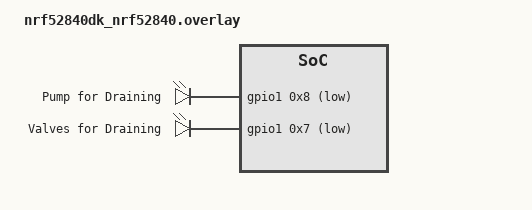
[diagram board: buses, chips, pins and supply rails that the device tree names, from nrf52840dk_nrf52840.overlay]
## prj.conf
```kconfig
#
# Copyright (c) 2019 Nordic Semiconductor ASA
#
# SPDX-License-Identifier: LicenseRef-BSD-5-Clause-Nordic
#
CONFIG_NCS_SAMPLES_DEFAULTS=y

# General configuration
CONFIG_SYSTEM_WORKQUEUE_STACK_SIZE=2048
CONFIG_FLASH=y
CONFIG_FLASH_MAP=y
CONFIG_FCB=y
CONFIG_SETTINGS=y
CONFIG_HWINFO=y
CONFIG_LOG=y
CONFIG_LOG_PRINTK=y

CONFIG_DK_LIBRARY=y
CONFIG_BT_MESH_DK_PROV=y

# Bluetooth configuration
CONFIG_BT=y
CONFIG_BT_COMPANY_ID=0x0059
CONFIG_BT_DEVICE_NAME="Drainage System"
CONFIG_BT_L2CAP_TX_MTU=69
CONFIG_BT_L2CAP_TX_BUF_COUNT=8
CONFIG_BT_LL_SW_SPLIT=y
CONFIG_BT_OBSERVER=y
CONFIG_BT_PERIPHERAL=y
CONFIG_BT_SETTINGS=y
CONFIG_BT_MAX_CONN=3

# Disable unused Bluetooth features
CONFIG_BT_CTLR_DUP_FILTER_LEN=0
CONFIG_BT_CTLR_LE_ENC=n
CONFIG_BT_DATA_LEN_UPDATE=n
CONFIG_BT_PHY_UPDATE=n
CONFIG_BT_CTLR_CHAN_SEL_2=n
CONFIG_BT_CTLR_MIN_USED_CHAN=n
CONFIG_BT_CTLR_PRIVACY=n

# Bluetooth Mesh configuration
CONFIG_BT_MESH=y
CONFIG_BT_MESH_RELAY=y
CONFIG_BT_MESH_FRIEND=y
CONFIG_BT_MESH_ADV_BUF_COUNT=13
CONFIG_BT_MESH_TX_SEG_MAX=10
CONFIG_BT_MESH_PB_GATT=y
CONFIG_BT_MESH_GATT_PROXY=y

# Bluetooth Mesh models
CONFIG_BT_MESH_ONOFF_SRV=y
CONFIG_BT_MESH_ONOFF_CLI=y
CONFIG_BT_MESH_LVL_SRV=y

#For Reset
CONFIG_REBOOT=y

#For nRF52 Dongle (enable if flashed over USB / Disable if FLashed over SWD)
CONFIG_BOARD_HAS_NRF5_BOOTLOADER=y
```

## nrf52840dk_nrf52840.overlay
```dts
/ {
    leds {
		compatible = "gpio-leds";
		pumpdrain: pump_drain {
			gpios = < &gpio1 0x8 0x11 >;
			label = "Pump for Draining";
		};
		valvesdrain: valves_drain {
			gpios = < &gpio1 0x7 0x11 >;
			label = "Valves for Draining";
		};
    };
	aliases {
		pumpdrain = &pumpdrain;
		valvesdrain = &valvesdrain;
	};
};
```

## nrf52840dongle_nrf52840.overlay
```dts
/ {
    leds {
		compatible = "gpio-leds";
		pumpdrain: pump_drain {
			gpios = < &gpio1 0xd 0x11 >;
			label = "Pump for Draining";
		};
		valvesdrain: valves_drain {
			gpios = < &gpio1 0xa 0x11 >;
			label = "Valves for Draining";
		};
    };
	aliases {
		pumpdrain = &pumpdrain;
		valvesdrain = &valvesdrain;
	};
};
```

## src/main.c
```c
#include "bm_blemesh.h"
#include "bm_simple_buttons_and_leds.h"
#include <zephyr.h>
#include <sys/reboot.h>
#include <bm_draniage_system.h>

/**@brief For Reseting the System
 */
void reset(){
  printk("Reboot now!\n");
  sys_reboot(SYS_REBOOT_COLD);
}

/**@brief Function for application main entry.
 */
void main(void) {
  // Start Application
  printk("Starting Application...\n");
  // Init MAC Address
  uint32_t LSB_MAC_Address = NRF_FICR->DEVICEADDR[0];
  printk("Preprogrammed Randomly Static MAC-Address (LSB): 0x%x, %u \n", LSB_MAC_Address, LSB_MAC_Address);
  // Init Leds
  bm_init_leds();
  //Init Reset Buttons
  bm_init_buttons(reset);
  // Start Mesh Operation
  bm_blemesh_enable(); // Will return faster than the Stack is realy ready... keep on waiting in the transition.

  while(true){
    bm_drainage_stateMachine();
    k_sleep(K_MSEC(1000));
  }

}
```

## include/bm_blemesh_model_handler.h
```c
/*
This file is part of Bluetooth-Benchamrk.

Bluetooth-Benchamrk is free software: you can redistribute it and/or modify
it under the terms of the GNU General Public License as published by
the Free Software Foundation, either version 3 of the License, or
(at your option) any later version.

Bluetooth-Benchamrk is distributed in the hope that it will be useful,
but WITHOUT ANY WARRANTY; without even the implied warranty of
MERCHANTABILITY or FITNESS FOR A PARTICULAR PURPOSE.  See the
GNU General Public License for more details.

You should have received a copy of the GNU General Public License
along with Bluetooth-Benchamrk.  If not, see <http://www.gnu.org/licenses/>.
*/

/* AUTHOR 	 :    Raffael Anklin       */

#ifndef MODEL_HANDLER_H__
#define MODEL_HANDLER_H__

#include <bm_draniage_system.h>
#include <bluetooth/mesh/models.h>


#ifdef __cplusplus
extern "C" {
#endif

extern struct bt_mesh_onoff_cli valve_drain_on_off_cli[NUMBER_OF_VALVES];

const struct bt_mesh_comp *bm_blemesh_model_handler_init(void);


#ifdef __cplusplus
}
#endif

#endif /* MODEL_HANDLER_H__ */
```

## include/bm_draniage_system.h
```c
#ifndef BM_DRAINAGE_H
#define BM_DRAINAGE_H

#define NUMBER_OF_VALVES 8

extern int16_t drain_intervall_h;
extern int16_t valve_drain_time_s[NUMBER_OF_VALVES];

void bm_drainage_stateMachine();



#endif
```

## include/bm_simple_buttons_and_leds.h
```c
/*
This file is part of Benchamrk-Shared-Library.

Benchamrk-Shared-Library is free software: you can redistribute it and/or modify
it under the terms of the GNU General Public License as published by
the Free Software Foundation, either version 3 of the License, or
(at your option) any later version.

Benchamrk-Shared-Library is distributed in the hope that it will be useful,
but WITHOUT ANY WARRANTY; without even the implied warranty of
MERCHANTABILITY or FITNESS FOR A PARTICULAR PURPOSE.  See the
GNU General Public License for more details.

You should have received a copy of the GNU General Public License
along with Benchamrk-Shared-Library.  If not, see <http://www.gnu.org/licenses/>.
*/

/* AUTHOR ZEPHYR_BLE_MESH  :   Raffael Anklin        */
/* AUTHOR NRF_SDK_ZIGBEE   :   Cyrill Horath        */


#ifdef __cplusplus
extern "C" {
#endif

#ifndef SIMPLE_BUTTONS_AND_LEDS_H
#define SIMPLE_BUTTONS_AND_LEDS_H


#include <zephyr.h>
#include <device.h>
#include <devicetree.h>
#include <devicetree_unfixed.h>
#include <drivers/gpio.h>
#include <sys/util.h>
#include <sys/slist.h>

/*
 * Devicetree helper macro which gets the 'flags' cell from a 'gpios'
 * property, or returns 0 if the property has no 'flags' cell.
 */

#define FLAGS_OR_ZERO(node)						\
	COND_CODE_1(DT_PHA_HAS_CELL(node, gpios, flags),		\
		    (DT_GPIO_FLAGS(node, gpios)),			\
		    (0))



/* The devicetree node identifier for the "led0" alias. */
#define LED0_NODE DT_ALIAS(led0)

#if DT_NODE_HAS_STATUS(LED0_NODE, okay)
#define LED0	DT_GPIO_LABEL(LED0_NODE, gpios)
#define PIN_LED0	DT_GPIO_PIN(LED0_NODE, gpios)
#if DT_PHA_HAS_CELL(LED0_NODE, gpios, flags)
#define FLAGS_LED0	DT_GPIO_FLAGS(LED0_NODE, gpios)
#endif
#else
/* A build error here means your board isn't set up to blink an LED. */
#error "Unsupported board: led0 devicetree alias is not defined"
#define LED0	""
#define PIN_LED0	0
#endif

#ifndef FLAGS_LED0
#define FLAGS_LED0	0
#endif

/* The devicetree node identifier for the "led1" alias. Is the RED LED on THe nRF52 Donlge*/
#define LED1_NODE DT_ALIAS(led1)

#if DT_NODE_HAS_STATUS(LED1_NODE, okay)
#define LED1	DT_GPIO_LABEL(LED1_NODE, gpios)
#define PIN_LED1	DT_GPIO_PIN(LED1_NODE, gpios)
#if DT_PHA_HAS_CELL(LED1_NODE, gpios, flags)
#define FLAGS_LED1	DT_GPIO_FLAGS(LED1_NODE, gpios)
#endif
#else
/* A build error here means your board isn't set up to blink an LED. */
#error "Unsupported board: led1 devicetree alias is not defined"
#define LED1	""
#define PIN_LED1	0
#endif

#ifndef FLAGS_LED1
#define FLAGS_LED1	0
#endif


/* The devicetree node identifier for the "led2" alias. Is the GREEN LED on THe nRF52 Donlge*/
#define LED2_NODE DT_ALIAS(led2)

#if DT_NODE_HAS_STATUS(LED2_NODE, okay)
#define LED2	DT_GPIO_LABEL(LED2_NODE, gpios)
#define PIN_LED2	DT_GPIO_PIN(LED2_NODE, gpios)
#if DT_PHA_HAS_CELL(LED2_NODE, gpios, flags)
#define FLAGS_LED2	DT_GPIO_FLAGS(LED2_NODE, gpios)
#endif
#else
/* A build error here means your board isn't set up to blink an LED. */
#error "Unsupported board: led2 devicetree alias is not defined"
#define LED2	""
#define PIN_LED2	0
#endif

#ifndef FLAGS_LED2
#define FLAGS_LED1	0
#endif

/* The devicetree node identifier for the "led3" alias. Is the BLUE LED on THe nRF52 Donlge*/
#define LED3_NODE DT_ALIAS(led3)

#if DT_NODE_HAS_STATUS(LED3_NODE, okay)
#define LED3	DT_GPIO_LABEL(LED3_NODE, gpios)
#define PIN_LED3	DT_GPIO_PIN(LED3_NODE, gpios)
#if DT_PHA_HAS_CELL(LED3_NODE, gpios, flags)
#define FLAGS_LED3	DT_GPIO_FLAGS(LED3_NODE, gpios)
#endif
#else
/* A build error here means your board isn't set up to blink an LED. */
#error "Unsupported board: led3 devicetree alias is not defined"
#define LED3	""
#define PIN_LED3	0
#endif

#ifndef FLAGS_LED3
#define FLAGS_LED3	0
#endif

/* The devicetree node identifier for the "pumpdrain" alias.*/
#define PUMPDRAIN_NODE DT_ALIAS(pumpdrain)

#if DT_NODE_HAS_STATUS(PUMPDRAIN_NODE, okay)
#define PUMPDRAIN	DT_GPIO_LABEL(PUMPDRAIN_NODE, gpios)
#define PIN_PUMPDRAIN	DT_GPIO_PIN(PUMPDRAIN_NODE, gpios)
#if DT_PHA_HAS_CELL(PUMPDRAIN_NODE, gpios, flags)
#define FLAGS_PUMPDRAIN	DT_GPIO_FLAGS(PUMPDRAIN_NODE, gpios)
#endif
#else
/* A build error here means your board isn't set up to blink an LED. */
#error "Unsupported board: pumpdrain devicetree alias is not defined"
#define PUMPDRAIN	""
#define PIN_PUMPDRAIN	0
#endif

#ifndef FLAGS_PUMPDRAIN
#define FLAGS_PUMPDRAIN	0
#endif

/* The devicetree node identifier for the "valvesdrain" alias.*/
#define VALVESDRAIN_NODE DT_ALIAS(valvesdrain)

#if DT_NODE_HAS_STATUS(VALVESDRAIN_NODE, okay)
#define VALVESDRAIN	DT_GPIO_LABEL(VALVESDRAIN_NODE, gpios)
#define PIN_VALVESDRAIN	DT_GPIO_PIN(VALVESDRAIN_NODE, gpios)
#if DT_PHA_HAS_CELL(VALVESDRAIN_NODE, gpios, flags)
#define FLAGS_VALVESDRAIN	DT_GPIO_FLAGS(VALVESDRAIN_NODE, gpios)
#endif
#else
/* A build error here means your board isn't set up to blink an LED. */
#error "Unsupported board: valvesdrain devicetree alias is not defined"
#define VALVESDRAIN	""
#define PIN_VALVESDRAIN	0
#endif

#ifndef FLAGS_VALVESDRAIN
#define FLAGS_VALVESDRAIN	0
#endif


/*
 * Get button configuration from the devicetree sw0 alias.
 *
 * At least a GPIO device and pin number must be provided. The 'flags'
 * cell is optional.
 */

#define SW0_NODE	DT_ALIAS(sw0)

#if DT_NODE_HAS_STATUS(SW0_NODE, okay)
#define SW0_GPIO_LABEL	DT_GPIO_LABEL(SW0_NODE, gpios)
#define SW0_GPIO_PIN	DT_GPIO_PIN(SW0_NODE, gpios)
#define SW0_GPIO_FLAGS	(GPIO_INPUT | FLAGS_OR_ZERO(SW0_NODE) | GPIO_INT_DEBOUNCE)
#else
#error "Unsupported board: sw0 devicetree alias is not defined"
#define SW0_GPIO_LABEL	""
#define SW0_GPIO_PIN	0
#define SW0_GPIO_FLAGS	0
#endif




/**
* Init the Buttons
*
*/
void bm_init_buttons(void (*button0_cb)());

/**
* Get the BUTTON0 Pressed State
*
* @return State of the BUTTON0 Pressed (0/1)
*/
bool bm_button0_pressed_state_get();
/**
* Get the BUTTON0 Toggled State
*
* @return State of the BUTTON0 Toggled State (0/1)
*/
bool bm_button0_toggle_state_get();

/**
* Set the BUTTON0 Toggled State
*
* @param State of the BUTTON0 Toggled State (0/1)
*/
void bm_button0_toggle_state_set(bool newstate);



/**
* Init the Leds
*
*/
void bm_init_leds();

/**
* Set the LED0 State
*
* @param State to set the LED0 to (0/1) (GREEN no RGB on nRF52 Dongle / LED1 on nRF52 DK)
*/
void bm_led0_set(bool state);

/**
* Get the LED0 State
*
* @return State of the LED0 (0/1) (GREEN no RGB on nRF52 Dongle / LED1 on nRF52 DK)
*/
bool bm_led0_get();


/**
* Set the LED1 State
*
* @param State to set the LED1 to (0/1) (RED on nRF52 Dongle / LED2 on nRF52 DK)
*/
void bm_led1_set(bool state);

/**
* Get the LED1 State
*
* @return State of the LED1 (0/1) (RED on nRF52 Dongle / LED2 on nRF52 DK)
*/
bool bm_led1_get();

/**
* Set the LED2 State
*
* @param State to set the LED2 to (0/1) (GREEN on nRF52 Dongle / LED3 on nRF52 DK)
*/
void bm_led2_set(bool state);

/**
* Get the LED2 State
*
* @return State of the LED2 (0/1) (GREEN on nRF52 Dongle / LED3 on nRF52 DK)
*/
bool bm_led2_get();

/**
* Set the LED3 State
*
* @param State to set the LED3 to (0/1) (BLUE on nRF52 Dongle / LED4 on nRF52 DK)
*/
void bm_led3_set(bool state);

/**
* Get the LED3 State
*
* @return State of the LED3 (0/1) (BLUE on nRF52 Dongle / LED4 on nRF52 DK)
*/
bool bm_led3_get();


/**
* Set the PUMPDRAIN State
*
* @param State to set the PUMPDRAIN to (0/1)
*/
void bm_pumpdrain_set(bool state);

/**
* Get the PUMPDRAIN State
*
* @return State of the PUMPDRAIN (0/1)
*/
bool bm_pumpdrain_get();

/**
* Set the VALVESDRAIN State
*
* @param State to set the VALVESDRAIN to (0/1)
*/
void bm_valvesdrain_set(bool state);

/**
* Get the VALVESDRAIN State
*
* @return State of the VALVESDRAIN (0/1)
*/
bool bm_valvesdrain_get();


#endif

#ifdef __cplusplus
}
#endif
```

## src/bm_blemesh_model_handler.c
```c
/*
This file is part of Bluetooth-Benchamrk.

Bluetooth-Benchamrk is free software: you can redistribute it and/or modify
it under the terms of the GNU General Public License as published by
the Free Software Foundation, either version 3 of the License, or
(at your option) any later version.

Bluetooth-Benchamrk is distributed in the hope that it will be useful,
but WITHOUT ANY WARRANTY; without even the implied warranty of
MERCHANTABILITY or FITNESS FOR A PARTICULAR PURPOSE.  See the
GNU General Public License for more details.

You should have received a copy of the GNU General Public License
along with Bluetooth-Benchamrk.  If not, see <http://www.gnu.org/licenses/>.
*/

/* AUTHOR 	 :    Raffael Anklin       */


#include "bm_simple_buttons_and_leds.h"
#include "bm_blemesh.h"
#include "bm_blemesh_model_handler.h"

#include <bluetooth/bluetooth.h>
#include <bluetooth/mesh/models.h>
#include <bluetooth/mesh/model_types.h>

#include <bm_draniage_system.h>


/* ============================================== Element 1 ============================== */

/** ON/OFF Server definition */
static void pump_set(struct bt_mesh_onoff_srv *srv, struct bt_mesh_msg_ctx *ctx,
					const struct bt_mesh_onoff_set *set,
					struct bt_mesh_onoff_status *rsp)
{
	// Set DK LED index
	bm_pumpdrain_set(set->on_off);
}

static void pump_get(struct bt_mesh_onoff_srv *srv, struct bt_mesh_msg_ctx *ctx,
					struct bt_mesh_onoff_status *rsp)
{
	rsp->present_on_off = bm_pumpdrain_get();
}

static const struct bt_mesh_onoff_srv_handlers pump_onoff_handlers = {
	.set = pump_set,
	.get = pump_get,
};

static struct bt_mesh_onoff_srv pump_on_off_srv = BT_MESH_ONOFF_SRV_INIT(&pump_onoff_handlers);

/** Convert level to percent */
static int16_t level_to_percent(int16_t level){
	return (double)((double)level+BT_MESH_LVL_MAX)*100/(BT_MESH_LVL_MAX*2);
}

/** Convert percent to level */
static int16_t percent_to_level(int16_t percent){
	return ((percent*2*BT_MESH_LVL_MAX)/100)-BT_MESH_LVL_MAX;
}

/** Time Drainage Intervall LEVEL Server definition */
static void drain_intervall_h_get(struct bt_mesh_lvl_srv *srv, struct bt_mesh_msg_ctx *ctx,
					struct bt_mesh_lvl_status *rsp)
{
	printk("Waittime get is %u hours\n",drain_intervall_h);
	rsp->current = percent_to_level(drain_intervall_h);
}
static void drain_intervall_h_set(struct bt_mesh_lvl_srv *srv, struct bt_mesh_msg_ctx *ctx,
					const struct bt_mesh_lvl_set *set,
					struct bt_mesh_lvl_status *rsp)
{
	drain_intervall_h = level_to_percent(set->lvl);
	printk("Waittime set is %u hours\n",drain_intervall_h);
}
static void dummy_delta_set(struct bt_mesh_lvl_srv *srv,
				struct bt_mesh_msg_ctx *ctx,
				const struct bt_mesh_lvl_delta_set *delta_set,
				struct bt_mesh_lvl_status *rsp)
{ 
	printk("Not Supported\n");
}
static void dummy_h_move_set(struct bt_mesh_lvl_srv *srv,
			       struct bt_mesh_msg_ctx *ctx,
			       const struct bt_mesh_lvl_move_set *move_set,
			       struct bt_mesh_lvl_status *rsp)
{
	printk("Not Supported\n");
}
static const struct bt_mesh_lvl_srv_handlers drain_intervall_h_lvl_handlers = {
	.set = drain_intervall_h_set,
	.get = drain_intervall_h_get,
	.delta_set = dummy_delta_set,
	.move_set = dummy_h_move_set
};
static struct bt_mesh_lvl_srv drain_intervall_h_lvl_srv = BT_MESH_LVL_SRV_INIT(&drain_intervall_h_lvl_handlers);

/** Health Server definition */
static void attention_on(struct bt_mesh_model *model)
{
	printk("attention_on()\n");
}

static void attention_off(struct bt_mesh_model *model)
{
	printk("attention_off()\n");
}
static const struct bt_mesh_health_srv_cb health_srv_cb = {
	.attn_on = attention_on,
	.attn_off = attention_off,
};

static struct bt_mesh_health_srv health_srv = {
	.cb = &health_srv_cb,
};

BT_MESH_HEALTH_PUB_DEFINE(health_pub, 0);


/* ============================================== Valve Elements ============================== */

/** ON/OFF Client definition */
struct bt_mesh_onoff_cli valve_drain_on_off_cli[NUMBER_OF_VALVES] = {
	[0 ... NUMBER_OF_VALVES -1] =  BT_MESH_ONOFF_CLI_INIT(NULL) ,
};

/** Drain Valves Open Time Seconds LEVEL Server definition */
static void valve_drain_time_s_get(struct bt_mesh_lvl_srv *srv, struct bt_mesh_msg_ctx *ctx,
					struct bt_mesh_lvl_status *rsp)
{
	rsp->current = percent_to_level(valve_drain_time_s[srv->model->elem_idx - 1]);
}
static void valve_drain_time_s_set(struct bt_mesh_lvl_srv *srv, struct bt_mesh_msg_ctx *ctx,
					const struct bt_mesh_lvl_set *set,
					struct bt_mesh_lvl_status *rsp)
{
	valve_drain_time_s[srv->model->elem_idx - 1] = level_to_percent(set->lvl);
}
static const struct bt_mesh_lvl_srv_handlers valve_drain_time_s_lvl_handlers = {
	.set = valve_drain_time_s_set,
	.get = valve_drain_time_s_get,
	.delta_set = dummy_delta_set,
	.move_set = dummy_h_move_set
};
static struct bt_mesh_lvl_srv valve_drain_time_s_lvl_srv[NUMBER_OF_VALVES] = {
	[0 ... NUMBER_OF_VALVES -1] =  BT_MESH_LVL_SRV_INIT(&valve_drain_time_s_lvl_handlers) ,
};




/* Define all Elements */
static struct bt_mesh_elem elements[1+ NUMBER_OF_VALVES] = {
	BT_MESH_ELEM(
		1, BT_MESH_MODEL_LIST(BT_MESH_MODEL_CFG_SRV, BT_MESH_MODEL_HEALTH_SRV(&health_srv, &health_pub), BT_MESH_MODEL_ONOFF_SRV(&pump_on_off_srv), BT_MESH_MODEL_LVL_SRV(&drain_intervall_h_lvl_srv)),
		BT_MESH_MODEL_NONE),
	BT_MESH_ELEM(
		2, BT_MESH_MODEL_LIST(BT_MESH_MODEL_ONOFF_CLI(&valve_drain_on_off_cli[0]), BT_MESH_MODEL_LVL_SRV(&valve_drain_time_s_lvl_srv[0])),
		BT_MESH_MODEL_NONE),
	BT_MESH_ELEM(
		3, BT_MESH_MODEL_LIST(BT_MESH_MODEL_ONOFF_CLI(&valve_drain_on_off_cli[1]), BT_MESH_MODEL_LVL_SRV(&valve_drain_time_s_lvl_srv[1])),
		BT_MESH_MODEL_NONE),
		BT_MESH_ELEM(
		4, BT_MESH_MODEL_LIST(BT_MESH_MODEL_ONOFF_CLI(&valve_drain_on_off_cli[2]), BT_MESH_MODEL_LVL_SRV(&valve_drain_time_s_lvl_srv[2])),
		BT_MESH_MODEL_NONE),
		BT_MESH_ELEM(
		5, BT_MESH_MODEL_LIST(BT_MESH_MODEL_ONOFF_CLI(&valve_drain_on_off_cli[3]), BT_MESH_MODEL_LVL_SRV(&valve_drain_time_s_lvl_srv[3])),
		BT_MESH_MODEL_NONE),
		BT_MESH_ELEM(
		6, BT_MESH_MODEL_LIST(BT_MESH_MODEL_ONOFF_CLI(&valve_drain_on_off_cli[4]), BT_MESH_MODEL_LVL_SRV(&valve_drain_time_s_lvl_srv[4])),
		BT_MESH_MODEL_NONE),
		BT_MESH_ELEM(
		7, BT_MESH_MODEL_LIST(BT_MESH_MODEL_ONOFF_CLI(&valve_drain_on_off_cli[5]), BT_MESH_MODEL_LVL_SRV(&valve_drain_time_s_lvl_srv[5])),
		BT_MESH_MODEL_NONE),
		BT_MESH_ELEM(
		8, BT_MESH_MODEL_LIST(BT_MESH_MODEL_ONOFF_CLI(&valve_drain_on_off_cli[6]), BT_MESH_MODEL_LVL_SRV(&valve_drain_time_s_lvl_srv[6])),
		BT_MESH_MODEL_NONE),
		BT_MESH_ELEM(
		9, BT_MESH_MODEL_LIST(BT_MESH_MODEL_ONOFF_CLI(&valve_drain_on_off_cli[7]), BT_MESH_MODEL_LVL_SRV(&valve_drain_time_s_lvl_srv[7])),
		BT_MESH_MODEL_NONE)
				};



/* Create Composition */
const struct bt_mesh_comp comp = {
	.cid = CONFIG_BT_COMPANY_ID,
	.elem = elements,
	.elem_count = ARRAY_SIZE(elements),
};

const struct bt_mesh_comp *bm_blemesh_model_handler_init(void)
{
	return &comp;
}
```

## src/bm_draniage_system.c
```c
/*
 * Copyright (c) 2016 Intel Corporation
 * Copyright (c) 2020 Nordic Semiconductor ASA
 *
 * SPDX-License-Identifier: Apache-2.0
 */

/**
 * @file Drainage System with Flowchart
 */

#include <zephyr.h>
#include <sys/printk.h>
#include <device.h>
#include <bm_draniage_system.h>
#include <bm_blemesh_model_handler.h>
#include <bluetooth/mesh/models.h>
#include <bm_simple_buttons_and_leds.h>

typedef enum {INIT,
				WAIT,
				CLOSE_ALL,
				DRAIN_VALVES,
				OPEN_ALL}  state_t;
 
state_t state = INIT;

int16_t drain_intervall_h = 12;
int16_t valve_drain_time_s[NUMBER_OF_VALVES] = {
	[0 ... NUMBER_OF_VALVES -1] = 10,
};

static int ret;
static struct bt_mesh_onoff_set set = {.on_off = false,};

void bm_drainage_stateMachine()
{
switch( state ) {
	case INIT:
		printk("State: INIT\n");
		bm_pumpdrain_set(false);
		bm_valvesdrain_set(false);
		k_sleep(K_MSEC(500));
      	state = CLOSE_ALL;
      	break;

    case CLOSE_ALL:
		printk("State: CLOSE_ALL\n");
		bm_valvesdrain_set(true);
		k_sleep(K_MSEC(2000));
	  	for (size_t i = 0; i < NUMBER_OF_VALVES; i++)
	  	{
			set.on_off = false;
			ret = bt_mesh_onoff_cli_set_unack(&valve_drain_on_off_cli[i],NULL,&set);
			k_sleep(K_MSEC(100));
	  	}	  
      	state = DRAIN_VALVES;
      	break;    
	
	case DRAIN_VALVES:
		printk("State: DRAIN_VALVES\n");
		bm_pumpdrain_set(true);
	  	for (size_t i = 0; i < NUMBER_OF_VALVES; i++)
	  	{
			set.on_off = true;
			ret = bt_mesh_onoff_cli_set_unack(&valve_drain_on_off_cli[i],NULL,&set);
			k_sleep(K_MSEC(valve_drain_time_s[i]*1000));
			set.on_off = false;
			ret = bt_mesh_onoff_cli_set_unack(&valve_drain_on_off_cli[i],NULL,&set);
			k_sleep(K_MSEC(500));
	  	}	  
      	state = OPEN_ALL;
      	break; 
	
	case OPEN_ALL:
		printk("State: OPEN_ALL\n");
	  	for (size_t i = 0; i < NUMBER_OF_VALVES; i++)
	  	{
			set.on_off = true;
			ret = bt_mesh_onoff_cli_set_unack(&valve_drain_on_off_cli[i],NULL,&set);
			k_sleep(K_MSEC(100));
	  	}	  
      	state = WAIT;
      	break; 
	
	case WAIT:
		printk("State: WAIT\n");
		bm_valvesdrain_set(false);
		bm_pumpdrain_set(false);
		printk("Wait for %u hours\n",drain_intervall_h);
      	k_sleep(K_HOURS(drain_intervall_h));
      	state = CLOSE_ALL;
      	break;
  }
}
```

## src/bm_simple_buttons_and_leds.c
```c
/*
This file is part of Benchmark-Shared-Library.

Benchmark-Shared-Library is free software: you can redistribute it and/or modify
it under the terms of the GNU General Public License as published by
the Free Software Foundation, either version 3 of the License, or
(at your option) any later version.

Benchmark-Shared-Library is distributed in the hope that it will be useful,
but WITHOUT ANY WARRANTY; without even the implied warranty of
MERCHANTABILITY or FITNESS FOR A PARTICULAR PURPOSE.  See the
GNU General Public License for more details.

You should have received a copy of the GNU General Public License
along with Benchmark-Shared-Library.  If not, see <http://www.gnu.org/licenses/>.
*/

/* AUTHOR ZEPHYR_BLE_MESH  :   Raffael Anklin        */
/* AUTHOR NRF_SDK_ZIGBEE   :   Cyrill Horath        */

#include "bm_simple_buttons_and_leds.h"


const struct device *dev_led0, *dev_led1, *dev_led2, *dev_led3, *dev_pumpdrain, *dev_valvesdrain, *dev_button0;
bool led0_is_on, led1_is_on, led2_is_on, led3_is_on, pumpdrain_is_on, valvesdrain_is_on = true;
bool button0_toggel_state = true;
int ret;

static struct gpio_callback button_cb_data;

static struct k_work_delayable buttons_debounce;

static void (*button0_callback)();

static void buttons_debounce_fn(struct k_work *work) {
  if(gpio_pin_get(dev_button0,SW0_GPIO_PIN)==true){
      button0_toggel_state = !button0_toggel_state;
      button0_callback();
  }
}


void button_pressed(const struct device *port,
					struct gpio_callback *cb,
					gpio_port_pins_t pins) {
  if (port == dev_button0) {
    k_work_reschedule(&buttons_debounce, K_MSEC(5*1000)); // Debounce the Button
                                                           //button0_callback();
  }
}

gpio_callback_handler_t button_pressed_handler = &button_pressed;


/* Init the Buttons */
void bm_init_buttons(void (*button0_cb)()) {
  dev_button0 = device_get_binding(SW0_GPIO_LABEL);
  if (dev_button0 == NULL) {
    printk("Error: didn't find %s device\n", SW0_GPIO_LABEL);
    return;
  }
  ret = gpio_pin_configure(dev_button0, SW0_GPIO_PIN, SW0_GPIO_FLAGS);
  if (ret != 0) {
    printk("Error %d: failed to configure %s pin %d\n",
        ret, SW0_GPIO_LABEL, SW0_GPIO_PIN);
    return;
  }
  ret = gpio_pin_interrupt_configure(dev_button0,
      SW0_GPIO_PIN,
      GPIO_INT_EDGE_TO_ACTIVE);
  if (ret != 0) {
    printk("Error %d: failed to configure interrupt on %s pin %d\n",
        ret, SW0_GPIO_LABEL, SW0_GPIO_PIN);
    return;
  }

  gpio_init_callback(&button_cb_data, button_pressed_handler, BIT(SW0_GPIO_PIN));
  gpio_add_callback(dev_button0, &button_cb_data);
  printk("Set up button at %s pin %d\n", SW0_GPIO_LABEL, SW0_GPIO_PIN);
  button0_callback = button0_cb;

  k_work_init_delayable(&buttons_debounce, buttons_debounce_fn);
}



/* Init the Leds */
void bm_init_leds() {
  dev_led0 = device_get_binding(LED0);
  if (dev_led0 == NULL) {
    printk("Error no LED0 found");
    return;
  }
  ret = gpio_pin_configure(dev_led0, PIN_LED0, GPIO_OUTPUT_INACTIVE | FLAGS_LED0);
  if (ret < 0) {
    printk("Error in configuration of led0 pin (err %d)", ret);
    return;
  }
  dev_led1 = device_get_binding(LED1);
  if (dev_led1 == NULL) {
    printk("Error no LED1 found");
    return;
  }
  ret = gpio_pin_configure(dev_led1, PIN_LED1, GPIO_OUTPUT_INACTIVE | FLAGS_LED1);
  if (ret < 0) {
    printk("Error in configuration of led1 pin (err %d)", ret);
    return;
  }
  dev_led2 = device_get_binding(LED2);
  if (dev_led2 == NULL) {
    printk("Error no LED2 found");
    return;
  }
  ret = gpio_pin_configure(dev_led2, PIN_LED2, GPIO_OUTPUT_INACTIVE | FLAGS_LED2);
  if (ret < 0) {
    printk("Error in configuration of led2 pin (err %d)", ret);
    return;
  }
  dev_led3 = device_get_binding(LED3);
  if (dev_led3 == NULL) {
    printk("Error no LED3 found");
    return;
  }
  ret = gpio_pin_configure(dev_led3, PIN_LED3, GPIO_OUTPUT_INACTIVE | FLAGS_LED3);
  if (ret < 0) {
    printk("Error in configuration of led3 pin (err %d)", ret);
    return;
  }

  dev_pumpdrain = device_get_binding(PUMPDRAIN);
  if (dev_pumpdrain == NULL) {
    printk("Error no PUMPDRAIN found");
    return;
  }
  ret = gpio_pin_configure(dev_pumpdrain, PIN_PUMPDRAIN, GPIO_OUTPUT_ACTIVE | FLAGS_PUMPDRAIN);
  if (ret < 0) {
    printk("Error in configuration of pumpdrain pin (err %d)", ret);
    return;
  }

  dev_valvesdrain = device_get_binding(VALVESDRAIN);
  if (dev_valvesdrain == NULL) {
    printk("Error no VALVESDRAIN found");
    return;
  }
  ret = gpio_pin_configure(dev_valvesdrain, PIN_VALVESDRAIN, GPIO_OUTPUT_ACTIVE | FLAGS_VALVESDRAIN);
  if (ret < 0) {
    printk("Error in configuration of valvesdrain pin (err %d)", ret);
    return;
  }


}


/* Set LED0. pca10059 -> Green LED */
void bm_led0_set(bool state) {
  gpio_pin_set(dev_led0, PIN_LED0, (int)state);
  led0_is_on = state;
}

/* Get LED0 */
bool bm_led0_get() {
  return led0_is_on;
}

/* Set LED1. pca10059 -> Red LED (RGB) */
void bm_led1_set(bool state) {
  gpio_pin_set(dev_led1, PIN_LED1, (int)state);
  led1_is_on = state;
}

/* Get LED1 */
bool bm_led1_get() {
  return led1_is_on;
}

/* Set LED2. pca10059 -> Green LED (RGB) */
void bm_led2_set(bool state) {
  gpio_pin_set(dev_led2, PIN_LED2, (int)state);
  led2_is_on = state;
}

/* Get LED2 */
bool bm_led2_get() {
  return led2_is_on;
}

/* Set LED3. pca10059 -> Blue LED (RGB)  */
void bm_led3_set(bool state) {
  gpio_pin_set(dev_led3, PIN_LED3, (int)state);
  led3_is_on = state;
}

/* Get LED3 */
bool bm_led3_get() {
  return led3_is_on;
}


/* Set PUMPDRAIN  */
void bm_pumpdrain_set(bool state) {
  gpio_pin_set(dev_pumpdrain, PIN_PUMPDRAIN, (int)state);
  pumpdrain_is_on = !state;
}

/* Get PUMPDRAIN */
bool bm_pumpdrain_get() {
  return pumpdrain_is_on;
}

/* Set VALVESDRAIN  */
void bm_valvesdrain_set(bool state) {
  gpio_pin_set(dev_valvesdrain, PIN_VALVESDRAIN, (int)state);
  valvesdrain_is_on = !state;
}

/* Get PUMPDRAIN */
bool bm_valvesdrain_get() {
  return valvesdrain_is_on;
}


/* Get BUTTON0 Pressed State*/
bool bm_button0_pressed_state_get() {
   return (bool) gpio_pin_get(dev_button0, SW0_GPIO_PIN);
}

/* Get BUTTON0 Toggled State*/
bool bm_button0_toggle_state_get() {
  //gpio_pin_get(dev_led0, PIN_LED0, (int)state);
  return button0_toggel_state;
}

/* Set BUTTON0 Toggled State*/
void bm_button0_toggle_state_set(bool newstate) {
  //gpio_pin_get(dev_led0, PIN_LED0, (int)state);
  button0_toggel_state = newstate;
}
```
